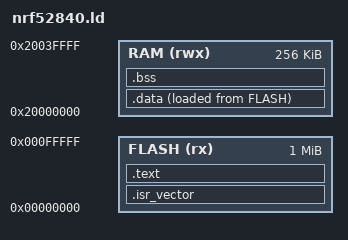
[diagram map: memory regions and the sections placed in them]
/* Nordic nRF52840 Linker Script (1 MB Flash, 256 KB SRAM) */
MEMORY
{
    FLASH (rx)  : ORIGIN = 0x00000000, LENGTH = 1024K
    RAM   (rwx) : ORIGIN = 0x20000000, LENGTH = 256K
}

_estack = ORIGIN(RAM) + LENGTH(RAM);

ENTRY(Reset_Handler)

SECTIONS
{
    .isr_vector :
    {
        KEEP(*(.isr_vector))
    } > FLASH

    .text :
    {
        *(.text*)
        *(.rodata*)
        . = ALIGN(4);
        _etext = .;
    } > FLASH

    _sidata = LOADADDR(.data);

    .data :
    {
        _sdata = .;
        *(.data*)
        . = ALIGN(4);
        _edata = .;
    } > RAM AT > FLASH

    .bss :
    {
        _sbss = .;
        *(.bss*)
        *(COMMON)
        . = ALIGN(4);
        _ebss = .;
        PROVIDE(end = .);
        PROVIDE(_end = .);
    } > RAM
}
